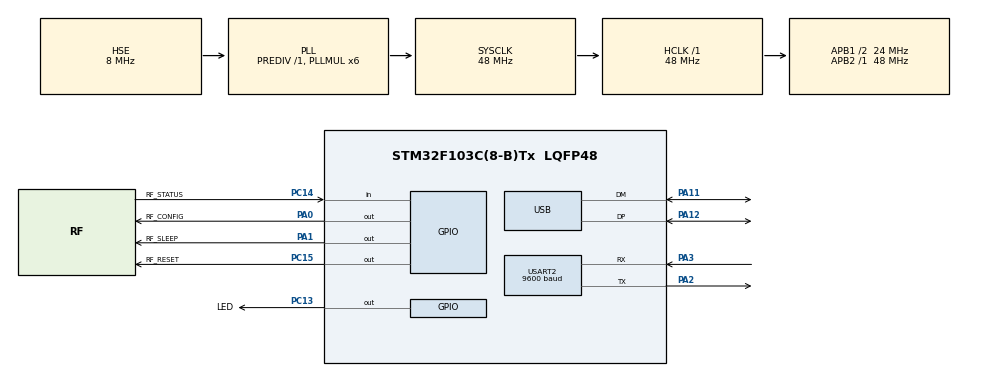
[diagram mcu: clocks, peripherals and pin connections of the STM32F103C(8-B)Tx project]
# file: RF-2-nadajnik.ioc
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Mcu.Family=STM32F1
Mcu.Name=STM32F103C(8-B)Tx
Mcu.Package=LQFP48
NVIC.PriorityGroup=NVIC_PRIORITYGROUP_4
NVIC.USART2_IRQn=true\:0\:0\:false\:false\:true\:true\:true
NVIC.USB_HP_CAN1_TX_IRQn=true\:0\:0\:false\:false\:true\:true\:true
NVIC.USB_LP_CAN1_RX0_IRQn=true\:0\:0\:false\:false\:true\:true\:true
PA0-WKUP.GPIO_Label=RF_CONFIG
PA0-WKUP.PinState=GPIO_PIN_SET
PA0-WKUP.Signal=GPIO_Output
PA1.GPIO_Label=RF_SLEEP
PA1.Signal=GPIO_Output
PA11.Mode=Device
PA11.Signal=USB_DM
PA12.Mode=Device
PA12.Signal=USB_DP
PA2.Mode=Asynchronous
PA2.Signal=USART2_TX
PA3.Mode=Asynchronous
PA3.Signal=USART2_RX
PC13-TAMPER-RTC.GPIO_Label=LED
PC13-TAMPER-RTC.Signal=GPIO_Output
PC14-OSC32_IN.GPIO_Label=RF_STATUS
PC14-OSC32_IN.Signal=GPIO_Input
PC15-OSC32_OUT.GPIO_Label=RF_RESET
PC15-OSC32_OUT.PinState=GPIO_PIN_SET
PC15-OSC32_OUT.Signal=GPIO_Output
PD0-OSC_IN.Mode=HSE-External-Oscillator
PD0-OSC_IN.Signal=RCC_OSC_IN
PD1-OSC_OUT.Mode=HSE-External-Oscillator
PD1-OSC_OUT.Signal=RCC_OSC_OUT
ProjectManager.HeapSize=0x200
ProjectManager.StackSize=0x400
ProjectManager.TargetToolchain=STM32CubeIDE
RCC.AHBFreq_Value=48000000
RCC.APB1CLKDivider=RCC_HCLK_DIV2
RCC.APB1Freq_Value=24000000
RCC.APB1TimFreq_Value=48000000
RCC.APB2Freq_Value=48000000
RCC.APB2TimFreq_Value=48000000
RCC.HCLKFreq_Value=48000000
RCC.PLLMUL=RCC_PLL_MUL6
RCC.SYSCLKFreq_VALUE=48000000
RCC.SYSCLKSource=RCC_SYSCLKSOURCE_PLLCLK
RCC.USBFreq_Value=48000000
USART2.BaudRate=9600
USART2.VirtualMode=VM_ASYNC
USB_DEVICE.CLASS_NAME_FS=CDC
USB_DEVICE.VirtualMode=Cdc
USB_DEVICE.VirtualModeFS=Cdc_FS
VP_SYS_VS_ND.Mode=No_Debug
VP_USB_DEVICE_VS_USB_DEVICE_CDC_FS.Mode=CDC_FS
board=custom

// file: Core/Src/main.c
/* USER CODE BEGIN Header */
/**
  ******************************************************************************
  * @file           : main.c
  * @brief          : Main program body
  ******************************************************************************
  * @attention
  *
  * <h2><center>&copy; Copyright (c) 2022 STMicroelectronics.
  * All rights reserved.</center></h2>
  *
  * This software component is licensed by ST under Ultimate Liberty license
  * SLA0044, the "License"; You may not use this file except in compliance with
  * the License. You may obtain a copy of the License at:
  *                             www.st.com/SLA0044
  *
  ******************************************************************************
  */
/* USER CODE END Header */
#include "main.h"
#include "usb_device.h"

/* USER CODE BEGIN Includes */
#include "usbd_cdc_if.h"
/* USER CODE END Includes */

UART_HandleTypeDef huart2;

/* USER CODE BEGIN PV */
uint8_t RxData[101];
uint8_t RxDataIndex=0;
uint8_t TxData[101];
uint8_t USB_TxData[111];
uint8_t USB_RxData[103];
/* USER CODE END PV */

void SystemClock_Config(void);
static void MX_GPIO_Init(void);
static void MX_USART2_UART_Init(void);

int main(void)
{

  /* MCU Configuration--------------------------------------------------------*/

  /* Reset of all peripherals, Initializes the Flash interface and the Systick. */
  HAL_Init();

  /* Configure the system clock */
  SystemClock_Config();

  /* Initialize all configured peripherals */
  MX_GPIO_Init();
  MX_USART2_UART_Init();
  MX_USB_DEVICE_Init();
  /* USER CODE BEGIN 2 */
  HAL_UART_Receive_IT(&huart2, &RxData[RxDataIndex], 1);
  /* USER CODE END 2 */

  /* Infinite loop */
  while (1)
  {
	  HAL_Delay(1000);
  }
}

void SystemClock_Config(void)
{
  RCC_OscInitTypeDef RCC_OscInitStruct = {0};
  RCC_ClkInitTypeDef RCC_ClkInitStruct = {0};
  RCC_PeriphCLKInitTypeDef PeriphClkInit = {0};

  /** Initializes the RCC Oscillators according to the specified parameters
  * in the RCC_OscInitTypeDef structure.
  */
  RCC_OscInitStruct.OscillatorType = RCC_OSCILLATORTYPE_HSE;
  RCC_OscInitStruct.HSEState = RCC_HSE_ON;
  RCC_OscInitStruct.HSEPredivValue = RCC_HSE_PREDIV_DIV1;
  RCC_OscInitStruct.HSIState = RCC_HSI_ON;
  RCC_OscInitStruct.PLL.PLLState = RCC_PLL_ON;
  RCC_OscInitStruct.PLL.PLLSource = RCC_PLLSOURCE_HSE;
  RCC_OscInitStruct.PLL.PLLMUL = RCC_PLL_MUL6;
  if (HAL_RCC_OscConfig(&RCC_OscInitStruct) != HAL_OK)
  {
    Error_Handler();
  }
  /** Initializes the CPU, AHB and APB buses clocks
  */
  RCC_ClkInitStruct.ClockType = RCC_CLOCKTYPE_HCLK|RCC_CLOCKTYPE_SYSCLK
                              |RCC_CLOCKTYPE_PCLK1|RCC_CLOCKTYPE_PCLK2;
  RCC_ClkInitStruct.SYSCLKSource = RCC_SYSCLKSOURCE_PLLCLK;
  RCC_ClkInitStruct.AHBCLKDivider = RCC_SYSCLK_DIV1;
  RCC_ClkInitStruct.APB1CLKDivider = RCC_HCLK_DIV2;
  RCC_ClkInitStruct.APB2CLKDivider = RCC_HCLK_DIV1;

  if (HAL_RCC_ClockConfig(&RCC_ClkInitStruct, FLASH_LATENCY_1) != HAL_OK)
  {
    Error_Handler();
  }
  PeriphClkInit.PeriphClockSelection = RCC_PERIPHCLK_USB;
  PeriphClkInit.UsbClockSelection = RCC_USBCLKSOURCE_PLL;
  if (HAL_RCCEx_PeriphCLKConfig(&PeriphClkInit) != HAL_OK)
  {
    Error_Handler();
  }
}

static void MX_USART2_UART_Init(void)
{

  huart2.Instance = USART2;
  huart2.Init.BaudRate = 9600;
  huart2.Init.WordLength = UART_WORDLENGTH_8B;
  huart2.Init.StopBits = UART_STOPBITS_1;
  huart2.Init.Parity = UART_PARITY_NONE;
  huart2.Init.Mode = UART_MODE_TX_RX;
  huart2.Init.HwFlowCtl = UART_HWCONTROL_NONE;
  huart2.Init.OverSampling = UART_OVERSAMPLING_16;
  if (HAL_UART_Init(&huart2) != HAL_OK)
  {
    Error_Handler();
  }

}

static void MX_GPIO_Init(void)
{
  GPIO_InitTypeDef GPIO_InitStruct = {0};

  /* GPIO Ports Clock Enable */
  __HAL_RCC_GPIOC_CLK_ENABLE();
  __HAL_RCC_GPIOD_CLK_ENABLE();
  __HAL_RCC_GPIOA_CLK_ENABLE();

  /*Configure GPIO pin Output Level */
  HAL_GPIO_WritePin(LED_GPIO_Port, LED_Pin, GPIO_PIN_RESET);

  /*Configure GPIO pin Output Level */
  HAL_GPIO_WritePin(RF_RESET_GPIO_Port, RF_RESET_Pin, GPIO_PIN_SET);

  /*Configure GPIO pin Output Level */
  HAL_GPIO_WritePin(RF_CONFIG_GPIO_Port, RF_CONFIG_Pin, GPIO_PIN_SET);

  /*Configure GPIO pin Output Level */
  HAL_GPIO_WritePin(RF_SLEEP_GPIO_Port, RF_SLEEP_Pin, GPIO_PIN_RESET);

  /*Configure GPIO pins : LED_Pin RF_RESET_Pin */
  GPIO_InitStruct.Pin = LED_Pin|RF_RESET_Pin;
  GPIO_InitStruct.Mode = GPIO_MODE_OUTPUT_PP;
  GPIO_InitStruct.Pull = GPIO_NOPULL;
  GPIO_InitStruct.Speed = GPIO_SPEED_FREQ_LOW;
  HAL_GPIO_Init(GPIOC, &GPIO_InitStruct);

  /*Configure GPIO pin : RF_STATUS_Pin */
  GPIO_InitStruct.Pin = RF_STATUS_Pin;
  GPIO_InitStruct.Mode = GPIO_MODE_INPUT;
  GPIO_InitStruct.Pull = GPIO_NOPULL;
  HAL_GPIO_Init(RF_STATUS_GPIO_Port, &GPIO_InitStruct);

  /*Configure GPIO pins : RF_CONFIG_Pin RF_SLEEP_Pin */
  GPIO_InitStruct.Pin = RF_CONFIG_Pin|RF_SLEEP_Pin;
  GPIO_InitStruct.Mode = GPIO_MODE_OUTPUT_PP;
  GPIO_InitStruct.Pull = GPIO_NOPULL;
  GPIO_InitStruct.Speed = GPIO_SPEED_FREQ_LOW;
  HAL_GPIO_Init(GPIOA, &GPIO_InitStruct);

}

void Error_Handler(void)
{
}

/************************ (C) COPYRIGHT STMicroelectronics *****END OF FILE****/
